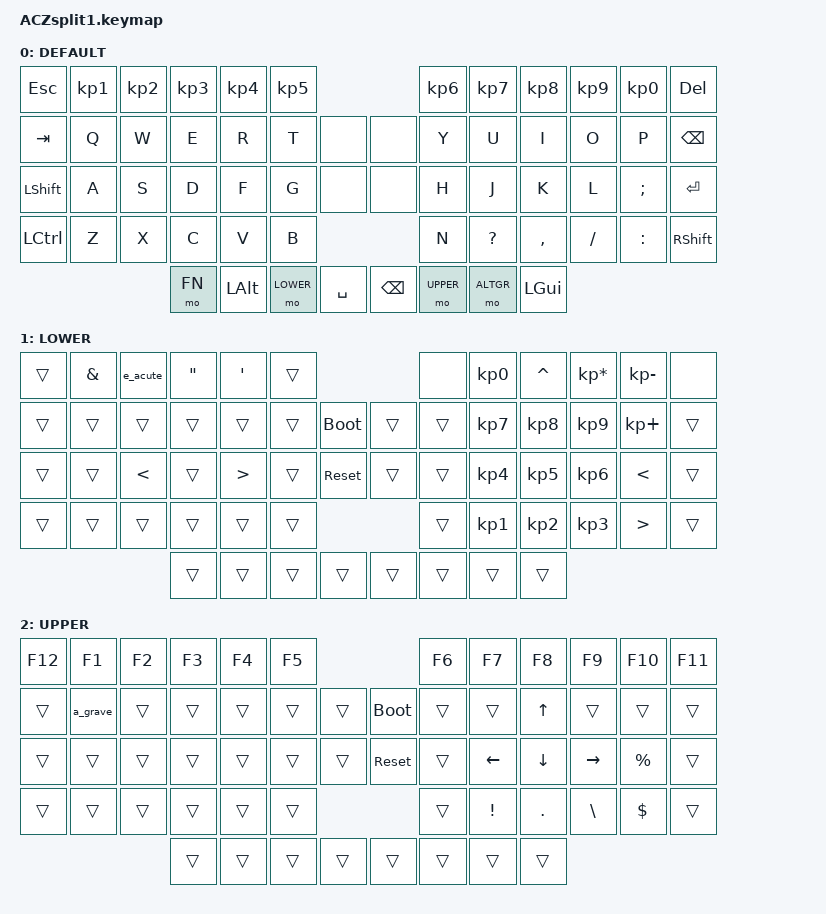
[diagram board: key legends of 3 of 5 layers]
#include <behaviors.dtsi>
#include <dt-bindings/zmk/keys.h>
#include <dt-bindings/zmk/bt.h>
#include <dt-bindings/zmk/outputs.h>    //allow selection between USB and BLE

#define DEFAULT 0
#define LOWER 1
#define UPPER 2
#define FN 3
#define ALTGR 4

/ {
    behaviors {
        // é = ALT+0130
        e_acute: e_acute {
            compatible = "zmk,behavior-macro";
            label = "E_ACUTE";
            #binding-cells = <0>;
            bindings =
                <&macro_press   &kp LALT>,
                <&macro_tap   &kp KP_N0 &kp KP_N1 &kp KP_N3 &kp KP_N0>,
                <&macro_release &kp LALT>;
        };

        // è = ALT+0138
        e_grave: e_grave {
            compatible = "zmk,behavior-macro";
            label = "E_GRAVE";
            #binding-cells = <0>;
            bindings =
                <&macro_press   &kp LALT>,
                <&macro_tap   &kp KP_N0 &kp KP_N1 &kp KP_N3 &kp KP_N8>,
                <&macro_release &kp LALT>;
        };

        // ù = alt+0151
        u_grave: u_grave {
            compatible = "zmk,behavior-macro";
            label = "U_GRAVE";
            #binding-cells = <0>;
            bindings =
                <&macro_press   &kp LALT>,
                <&macro_tap   &kp KP_N0 &kp KP_N1 &kp KP_N5 &kp KP_N1>,
                <&macro_release &kp LALT>;
        };

        // à = ALT+0133
        a_grave: a_grave {
            compatible = "zmk,behavior-macro";
            label = "A_GRAVE";
            #binding-cells = <0>;
            bindings =
                <&macro_press   &kp LALT>,
                <&macro_tap   &kp KP_N0 &kp KP_N1 &kp KP_N3 &kp KP_N3>,
                <&macro_release &kp LALT>;
        };

        //€ = ALT+0128
                euro: euro {
            compatible = "zmk,behavior-macro";
            label = "EURO";
            #binding-cells = <0>;
            wait-ms = <0>;
            tap-ms  = <0>;
            bindings =
                <&macro_press   &kp LALT>,
                <&macro_tap   &kp KP_N0 &kp KP_N1 &kp KP_N2 &kp KP_N8>,
                <&macro_release &kp LALT>;
        };

        //ç = ALT+0135
        c_cedilla: c_cedilla {
          compatible = "zmk,behavior-macro";
          label = "C_CEDILLA";
          #binding-cells = <0>;
            bindings =
                <&macro_press   &kp LALT>,
                <&macro_tap   &kp KP_N0 &kp KP_N1 &kp KP_N3 &kp KP_N5>,
                <&macro_release &kp LALT>;
        };

        //£ = ALT+0156
        pound: pound {
            compatible = "zmk,behavior-macro";
            label = "POUND";
            #binding-cells = <0>;
            wait-ms = <40>;
            tap-ms  = <40>;
            bindings =
                <&macro_press   &kp LALT>
                , <&macro_tap   &kp KP_N0 &kp KP_N1 &kp KP_N5 &kp KP_N6>
                , <&macro_release &kp LALT>
                ;
        };
    };

  
    keymap {
        compatible = "zmk,keymap";

        default_layer {
            label = "DEFAULT";

        //  ┏━━━━━━━━━━━┳━━━━━━━━━━━┳━━━━━━━━━━━┳━━━━━━━━━━━┳━━━━━━━━━━━┳━━━━━━━━━━━┓                           ┏━━━━━━━━━━━┳━━━━━━━━━━━┳━━━━━━━━━━━┳━━━━━━━━━━━┳━━━━━━━━━━━┳━━━━━━━━━━━┓
        //  ┃    ESP    ┃     1     ┃     2     ┃     3     ┃     4     ┃     5     ┃                           ┃     6     ┃     7     ┃     8     ┃     9     ┃     O     ┃    DEL    ┃
        //  ┣━━━━━━━━━━━╋━━━━━━━━━━━╋━━━━━━━━━━━╋━━━━━━━━━━━╋━━━━━━━━━━━╋━━━━━━━━━━━╋━━━━━━━━━━━┓   ┏━━━━━━━━━━━╋━━━━━━━━━━━╋━━━━━━━━━━━╋━━━━━━━━━━━╋━━━━━━━━━━━╋━━━━━━━━━━━╋━━━━━━━━━━━┫
        //  ┃    TAB    ┃     A     ┃     Z     ┃     E     ┃     R     ┃     T     ┃    N/A    ┃   ┃    N/A    ┃     Y     ┃     U     ┃     I     ┃     O     ┃     P     ┃    BSPC   ┃
        //  ┣━━━━━━━━━━━╋━━━━━━━━━━━╋━━━━━━━━━━━╋━━━━━━━━━━━╋━━━━━━━━━━━╋━━━━━━━━━━━╋━━━━━━━━━━━┫   ┣━━━━━━━━━━━╋━━━━━━━━━━━╋━━━━━━━━━━━╋━━━━━━━━━━━╋━━━━━━━━━━━╋━━━━━━━━━━━╋━━━━━━━━━━━┫
        //  ┃   SHIFT   ┃     Q     ┃     S     ┃     D     ┃     F     ┃     G     ┃    N/A    ┃   ┃    N/A    ┃     H     ┃     J     ┃     K     ┃     L     ┃     M     ┃   ENTER   ┃
        //  ┣━━━━━━━━━━━╋━━━━━━━━━━━╋━━━━━━━━━━━╋━━━━━━━━━━━╋━━━━━━━━━━━╋━━━━━━━━━━━╋━━━━━━━━━━━┛   ┗━━━━━━━━━━━╋━━━━━━━━━━━╋━━━━━━━━━━━╋━━━━━━━━━━━╋━━━━━━━━━━━╋━━━━━━━━━━━╋━━━━━━━━━━━┫
        //  ┃    CTRL   ┃     W     ┃     X     ┃     C     ┃     V     ┃     B     ┃                           ┃     N     ┃     ?     ┃     ,     ┃     /     ┃     :     ┃   SHIFT   ┃
        //  ┗━━━━━━━━━━━┻━━━━━━━━━━━┻━━━━━━━━━━━╋━━━━━━━━━━━╋━━━━━━━━━━━╋━━━━━━━━━━━╋━━━━━━━━━━━┓   ┏━━━━━━━━━━━╋━━━━━━━━━━━╋━━━━━━━━━━━╋━━━━━━━━━━━╋━━━━━━━━━━━┻━━━━━━━━━━━┻━━━━━━━━━━━┛
        //                                      ┃    FN     ┃    ALT    ┃   LOWER   ┃   SPACE   ┃   ┃    BSPC   ┃   UPPER   ┃   ALTGR   ┃     OS    ┃
        //                                      ┗━━━━━━━━━━━┻━━━━━━━━━━━┻━━━━━━━━━━━┻━━━━━━━━━━━┛   ┗━━━━━━━━━━━┻━━━━━━━━━━━┻━━━━━━━━━━━┻━━━━━━━━━━━┛
        //  |           |           |           |           |           |           |           |   |           |           |           |           |           |           |           |
        bindings = <
            &kp ESC     &kp KP_N1   &kp KP_N2   &kp KP_N3   &kp KP_N4   &kp KP_N5                               &kp KP_N6   &kp KP_N7   &kp KP_N8   &kp KP_N9   &kp KP_N0   &kp DEL
            &kp TAB     &kp Q       &kp W       &kp E       &kp R       &kp T       &none           &none       &kp Y       &kp U       &kp I       &kp O       &kp P       &kp BSPC
            &kp LSHIFT  &kp A       &kp S       &kp D       &kp F       &kp G       &none           &none       &kp H       &kp J       &kp K       &kp L       &kp SEMI    &kp ENTER
            &kp LCTRL   &kp Z       &kp X       &kp C       &kp V       &kp B                                   &kp N       &kp QMARK   &kp COMMA   &kp SLASH   &kp COLON   &kp RSHIFT
                                                &mo FN      &kp LALT   &mo LOWER   &kp SPACE          &kp BSPC    &mo UPPER   &mo ALTGR   &kp LGUI
            >;
        };

        lower_layer {
        label = "LOWER";
    
        //  ┏━━━━━━━━━━━┳━━━━━━━━━━━┳━━━━━━━━━━━┳━━━━━━━━━━━┳━━━━━━━━━━━┳━━━━━━━━━━━┓                           ┏━━━━━━━━━━━┳━━━━━━━━━━━┳━━━━━━━━━━━┳━━━━━━━━━━━┳━━━━━━━━━━━┳━━━━━━━━━━━┓
        //  ┃           ┃     &     ┃     é     ┃     "     ┃     '     ┃           ┃                           ┃           ┃     0     ┃     ^     ┃     *     ┃     -     ┃           ┃
        //  ┣━━━━━━━━━━━╋━━━━━━━━━━━╋━━━━━━━━━━━╋━━━━━━━━━━━╋━━━━━━━━━━━╋━━━━━━━━━━━╋━━━━━━━━━━━┓   ┏━━━━━━━━━━━╋━━━━━━━━━━━╋━━━━━━━━━━━╋━━━━━━━━━━━╋━━━━━━━━━━━╋━━━━━━━━━━━╋━━━━━━━━━━━┫
        //  ┃           ┃           ┃           ┃     ^     ┃           ┃           ┃ BOOTLOADER┃   ┃           ┃           ┃     7     ┃     8     ┃     9     ┃     +     ┃           ┃
        //  ┣━━━━━━━━━━━╋━━━━━━━━━━━╋━━━━━━━━━━━╋━━━━━━━━━━━╋━━━━━━━━━━━╋━━━━━━━━━━━╋━━━━━━━━━━━┫   ┣━━━━━━━━━━━╋━━━━━━━━━━━╋━━━━━━━━━━━╋━━━━━━━━━━━╋━━━━━━━━━━━╋━━━━━━━━━━━╋━━━━━━━━━━━┫
        //  ┃           ┃           ┃     <     ┃           ┃     >     ┃           ┃  SYS RST  ┃   ┃           ┃           ┃     4     ┃     5     ┃     6     ┃     <     ┃           ┃
        //  ┣━━━━━━━━━━━╋━━━━━━━━━━━╋━━━━━━━━━━━╋━━━━━━━━━━━╋━━━━━━━━━━━╋━━━━━━━━━━━╋━━━━━━━━━━━┛   ┗━━━━━━━━━━━╋━━━━━━━━━━━╋━━━━━━━━━━━╋━━━━━━━━━━━╋━━━━━━━━━━━╋━━━━━━━━━━━╋━━━━━━━━━━━┫
        //  ┃           ┃           ┃           ┃           ┃           ┃           ┃                           ┃           ┃     1     ┃     2     ┃     3     ┃     >     ┃           ┃
        //  ┗━━━━━━━━━━━┻━━━━━━━━━━━┻━━━━━━━━━━━╋━━━━━━━━━━━╋━━━━━━━━━━━╋━━━━━━━━━━━╋━━━━━━━━━━━┓   ┏━━━━━━━━━━━╋━━━━━━━━━━━╋━━━━━━━━━━━╋━━━━━━━━━━━╋━━━━━━━━━━━┻━━━━━━━━━━━┻━━━━━━━━━━━┛
        //                                      ┃           ┃           ┃           ┃           ┃   ┃           ┃           ┃           ┃           ┃
        //                                      ┗━━━━━━━━━━━┻━━━━━━━━━━━┻━━━━━━━━━━━┻━━━━━━━━━━━┛   ┗━━━━━━━━━━━┻━━━━━━━━━━━┻━━━━━━━━━━━┻━━━━━━━━━━━┛
        bindings = <
        //  |           |           |           |           |           |           |           |   |           |           |           |           |           |           |           |
            &trans      &kp AMPS    &e_acute    &kp DQT     &kp APOS    &trans                                  &none       &kp KP_N0   &kp CARET   &kp KP_MULTIPLY &kp KP_MINUS &none
            &trans      &trans      &trans      &trans      &trans      &trans      &bootloader     &trans &trans      &kp KP_N7   &kp KP_N8   &kp KP_N9   &kp KP_PLUS &trans
            &trans      &trans      &kp LESS_THAN &trans &kp GREATER_THAN &trans    &sys_reset      &trans      &trans      &kp KP_N4   &kp KP_N5   &kp KP_N6   &kp LT      &trans
            &trans      &trans      &trans      &trans      &trans      &trans                                  &trans      &kp KP_N1   &kp KP_N2   &kp KP_N3   &kp GT      &trans
                                                &trans      &trans      &trans      &trans          &trans      &trans      &trans      &trans
            >;
        };

        upper_layer {
          label = "UPPER";

        //  ┏━━━━━━━━━━━┳━━━━━━━━━━━┳━━━━━━━━━━━┳━━━━━━━━━━━┳━━━━━━━━━━━┳━━━━━━━━━━━┓                           ┏━━━━━━━━━━━┳━━━━━━━━━━━┳━━━━━━━━━━━┳━━━━━━━━━━━┳━━━━━━━━━━━┳━━━━━━━━━━━┓
        //  ┃    F12    ┃     F1    ┃     F2    ┃     F3    ┃     F4    ┃     F5    ┃                           ┃     F6    ┃     F7    ┃     F8    ┃     F9    ┃    F10    ┃    F11    ┃
        //  ┣━━━━━━━━━━━╋━━━━━━━━━━━╋━━━━━━━━━━━╋━━━━━━━━━━━╋━━━━━━━━━━━╋━━━━━━━━━━━╋━━━━━━━━━━━┓   ┏━━━━━━━━━━━╋━━━━━━━━━━━╋━━━━━━━━━━━╋━━━━━━━━━━━╋━━━━━━━━━━━╋━━━━━━━━━━━╋━━━━━━━━━━━┫
        //  ┃           ┃     à     ┃           ┃     ^     ┃           ┃           ┃           ┃   ┃ BOOTLOADER┃           ┃           ┃     UP    ┃           ┃           ┃           ┃
        //  ┣━━━━━━━━━━━╋━━━━━━━━━━━╋━━━━━━━━━━━╋━━━━━━━━━━━╋━━━━━━━━━━━╋━━━━━━━━━━━╋━━━━━━━━━━━┫   ┣━━━━━━━━━━━╋━━━━━━━━━━━╋━━━━━━━━━━━╋━━━━━━━━━━━╋━━━━━━━━━━━╋━━━━━━━━━━━╋━━━━━━━━━━━┫
        //  ┃           ┃           ┃           ┃           ┃           ┃           ┃           ┃   ┃  SYS RST  ┃           ┃   RIGHT   ┃    DOWN   ┃    LEFT   ┃     %     ┃           ┃
        //  ┣━━━━━━━━━━━╋━━━━━━━━━━━╋━━━━━━━━━━━╋━━━━━━━━━━━╋━━━━━━━━━━━╋━━━━━━━━━━━╋━━━━━━━━━━━┛   ┗━━━━━━━━━━━╋━━━━━━━━━━━╋━━━━━━━━━━━╋━━━━━━━━━━━╋━━━━━━━━━━━╋━━━━━━━━━━━╋━━━━━━━━━━━┫
        //  ┃           ┃           ┃           ┃           ┃           ┃           ┃                           ┃           ┃     !     ┃     .     ┃     \     ┃     $     ┃           ┃
        //  ┗━━━━━━━━━━━┻━━━━━━━━━━━┻━━━━━━━━━━━╋━━━━━━━━━━━╋━━━━━━━━━━━╋━━━━━━━━━━━╋━━━━━━━━━━━┓   ┏━━━━━━━━━━━╋━━━━━━━━━━━╋━━━━━━━━━━━╋━━━━━━━━━━━╋━━━━━━━━━━━┻━━━━━━━━━━━┻━━━━━━━━━━━┛
        //                                      ┃           ┃           ┃           ┃           ┃   ┃           ┃           ┃           ┃           ┃
        //                                      ┗━━━━━━━━━━━┻━━━━━━━━━━━┻━━━━━━━━━━━┻━━━━━━━━━━━┛   ┗━━━━━━━━━━━┻━━━━━━━━━━━┻━━━━━━━━━━━┻━━━━━━━━━━━┛
        bindings = <
        //  |           |           |           |           |           |           |           |   |           |           |           |           |           |           |           |
            &kp F12     &kp F1      &kp F2      &kp F3      &kp F4      &kp F5                                  &kp F6      &kp F7      &kp F8      &kp F9     &kp F10     &kp F11  
            &trans      &a_grave    &trans      &trans      &trans      &trans      &trans          &bootloader &trans      &trans      &kp UP      &trans      &trans      &trans
            &trans      &trans      &trans      &trans      &trans      &trans      &trans          &sys_reset  &trans      &kp LEFT    &kp DOWN    &kp RIGHT   &kp PERCENT &trans
            &trans      &trans      &trans      &trans      &trans      &trans                                  &trans      &kp EXCL    &kp DOT     &kp BACKSLASH &kp DOLLAR &trans
                                                &trans      &trans      &trans      &trans          &trans      &trans      &trans      &trans
            >;
        };

        fn_layer {
        label = "FN";
        
        //  ┏━━━━━━━━━━━┳━━━━━━━━━━━┳━━━━━━━━━━━┳━━━━━━━━━━━┳━━━━━━━━━━━┳━━━━━━━━━━━┓                           ┏━━━━━━━━━━━┳━━━━━━━━━━━┳━━━━━━━━━━━┳━━━━━━━━━━━┳━━━━━━━━━━━┳━━━━━━━━━━━┓
        //  ┃ ZMK STUDIO┃    PREV   ┃PLAY  PAUSE┃    NEXT   ┃ VOL DOWN  ┃  VOL  UP  ┃                           ┃    MUTE   ┃    CALC   ┃           ┃           ┃           ┃           ┃
        //  ┣━━━━━━━━━━━╋━━━━━━━━━━━╋━━━━━━━━━━━╋━━━━━━━━━━━╋━━━━━━━━━━━╋━━━━━━━━━━━╋━━━━━━━━━━━┓   ┏━━━━━━━━━━━╋━━━━━━━━━━━╋━━━━━━━━━━━╋━━━━━━━━━━━╋━━━━━━━━━━━╋━━━━━━━━━━━╋━━━━━━━━━━━┫
        //  ┃           ┃           ┃           ┃           ┃           ┃           ┃  BT CLEAR ┃   ┃           ┃           ┃           ┃           ┃           ┃           ┃           ┃
        //  ┣━━━━━━━━━━━╋━━━━━━━━━━━╋━━━━━━━━━━━╋━━━━━━━━━━━╋━━━━━━━━━━━╋━━━━━━━━━━━╋━━━━━━━━━━━┫   ┣━━━━━━━━━━━╋━━━━━━━━━━━╋━━━━━━━━━━━╋━━━━━━━━━━━╋━━━━━━━━━━━╋━━━━━━━━━━━╋━━━━━━━━━━━┫
        //  ┃           ┃           ┃           ┃           ┃           ┃           ┃           ┃   ┃           ┃           ┃           ┃           ┃           ┃           ┃           ┃
        //  ┣━━━━━━━━━━━╋━━━━━━━━━━━╋━━━━━━━━━━━╋━━━━━━━━━━━╋━━━━━━━━━━━╋━━━━━━━━━━━╋━━━━━━━━━━━┛   ┗━━━━━━━━━━━╋━━━━━━━━━━━╋━━━━━━━━━━━╋━━━━━━━━━━━╋━━━━━━━━━━━╋━━━━━━━━━━━╋━━━━━━━━━━━┫
        //  ┃           ┃    BT 1   ┃    BT 2   ┃    BT 3   ┃           ┃           ┃                           ┃           ┃           ┃           ┃           ┃           ┃           ┃
        //  ┗━━━━━━━━━━━┻━━━━━━━━━━━┻━━━━━━━━━━━╋━━━━━━━━━━━╋━━━━━━━━━━━╋━━━━━━━━━━━╋━━━━━━━━━━━┓   ┏━━━━━━━━━━━╋━━━━━━━━━━━╋━━━━━━━━━━━╋━━━━━━━━━━━╋━━━━━━━━━━━┻━━━━━━━━━━━┻━━━━━━━━━━━┛
        //                                      ┃           ┃           ┃           ┃           ┃   ┃           ┃           ┃           ┃           ┃
        //                                      ┗━━━━━━━━━━━┻━━━━━━━━━━━┻━━━━━━━━━━━┻━━━━━━━━━━━┛   ┗━━━━━━━━━━━┻━━━━━━━━━━━┻━━━━━━━━━━━┻━━━━━━━━━━━┛
        bindings = <
        //  |           |           |           |           |           |           |           |   |           |           |           |           |           |           |           |
            &studio_unlock &kp C_PREV  &kp C_PLAY_PAUSE &kp C_NEXT &kp C_VOL_DN &kp C_VOL_UP                    &kp C_MUTE  &kp K_CALC  &trans      &trans      &trans      &trans
            &trans      &trans      &trans      &trans      &trans      &trans      &bt BT_CLR      &trans      &trans      &trans      &trans      &trans      &trans      &trans 
            &trans      &trans      &trans      &trans      &trans      &trans      &trans          &trans      &trans      &trans      &trans      &trans      &trans      &trans 
            &trans      &bt BT_SEL 0 &bt BT_SEL 1 &bt BT_SEL 2 &trans  &trans   &trans              &trans      &trans      &trans      &trans      &trans      &trans      &trans 
                                                &trans      &trans      &trans      &trans          &trans      &trans      &trans      &trans
            >;
        };

        altgr_layer {
        label = "ALTGR";

        //  ┏━━━━━━━━━━━┳━━━━━━━━━━━┳━━━━━━━━━━━┳━━━━━━━━━━━┳━━━━━━━━━━━┳━━━━━━━━━━━┓                           ┏━━━━━━━━━━━┳━━━━━━━━━━━┳━━━━━━━━━━━┳━━━━━━━━━━━┳━━━━━━━━━━━┳━━━━━━━━━━━┓
        //  ┃           ┃     ~     ┃     è     ┃     #     ┃     `     ┃           ┃                           ┃           ┃           ┃           ┃           ┃           ┃           ┃
        //  ┣━━━━━━━━━━━╋━━━━━━━━━━━╋━━━━━━━━━━━╋━━━━━━━━━━━╋━━━━━━━━━━━╋━━━━━━━━━━━╋━━━━━━━━━━━┓   ┏━━━━━━━━━━━╋━━━━━━━━━━━╋━━━━━━━━━━━╋━━━━━━━━━━━╋━━━━━━━━━━━╋━━━━━━━━━━━╋━━━━━━━━━━━┫
        //  ┃           ┃     @     ┃     {     ┃     €     ┃     }     ┃           ┃           ┃   ┃           ┃           ┃     ù     ┃           ┃           ┃           ┃           ┃
        //  ┣━━━━━━━━━━━╋━━━━━━━━━━━╋━━━━━━━━━━━╋━━━━━━━━━━━╋━━━━━━━━━━━╋━━━━━━━━━━━╋━━━━━━━━━━━┫   ┣━━━━━━━━━━━╋━━━━━━━━━━━╋━━━━━━━━━━━╋━━━━━━━━━━━╋━━━━━━━━━━━╋━━━━━━━━━━━╋━━━━━━━━━━━┫
        //  ┃           ┃           ┃     (     ┃           ┃     )     ┃           ┃           ┃   ┃           ┃           ┃           ┃           ┃     £     ┃           ┃           ┃
        //  ┣━━━━━━━━━━━╋━━━━━━━━━━━╋━━━━━━━━━━━╋━━━━━━━━━━━╋━━━━━━━━━━━╋━━━━━━━━━━━╋━━━━━━━━━━━┛   ┗━━━━━━━━━━━╋━━━━━━━━━━━╋━━━━━━━━━━━╋━━━━━━━━━━━╋━━━━━━━━━━━╋━━━━━━━━━━━╋━━━━━━━━━━━┫
        //  ┃           ┃           ┃     [     ┃           ┃     ]     ┃           ┃                           ┃           ┃           ┃           ┃     |     ┃     ;     ┃           ┃
        //  ┗━━━━━━━━━━━┻━━━━━━━━━━━┻━━━━━━━━━━━╋━━━━━━━━━━━╋━━━━━━━━━━━╋━━━━━━━━━━━╋━━━━━━━━━━━┓   ┏━━━━━━━━━━━╋━━━━━━━━━━━╋━━━━━━━━━━━╋━━━━━━━━━━━╋━━━━━━━━━━━┻━━━━━━━━━━━┻━━━━━━━━━━━┛
        //                                      ┃           ┃           ┃           ┃           ┃   ┃           ┃           ┃           ┃           ┃
        //                                      ┗━━━━━━━━━━━┻━━━━━━━━━━━┻━━━━━━━━━━━┻━━━━━━━━━━━┛   ┗━━━━━━━━━━━┻━━━━━━━━━━━┻━━━━━━━━━━━┻━━━━━━━━━━━┛
        bindings = <
        //  |           |           |           |           |           |           |           |   |           |           |           |           |           |           |           |
            &trans      &kp TILDE   &e_grave    &kp HASH    &kp GRAVE   &trans                                  &trans      &trans      &trans      &trans      &kp UNDERSCORE &trans
            &trans      &kp AT      &kp LEFT_BRACE &euro    &kp RIGHT_BRACE &trans  &trans          &trans      &trans      &u_grave    &trans      &trans      &trans      &trans
            &trans      &trans      &kp LEFT_PARENTHESIS &trans &kp RIGHT_PARENTHESIS &trans &trans &trans      &trans      &trans      &trans      &pound      &trans      &trans 
            &trans      &trans      &kp LEFT_BRACKET &c_cedilla &kp RIGHT_BRACKET &trans &trans                 &trans      &trans      &trans      &kp PIPE    &kp SEMICOLON  &trans 
                                                &trans      &trans      &trans      &trans          &trans      &trans      &trans      &trans
            >;
        };

    };
 };
